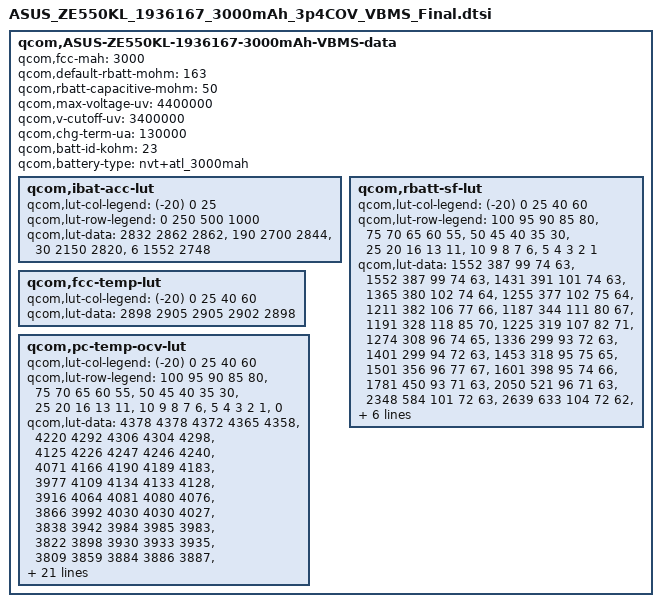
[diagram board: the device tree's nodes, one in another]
 qcom,ASUS-ZE550KL-1936167-3000mAh-VBMS-data {
	qcom,fcc-mah = <3000>;
	qcom,default-rbatt-mohm = <163>;
	qcom,rbatt-capacitive-mohm = <50>;
	qcom,max-voltage-uv = <4400000>;
	qcom,v-cutoff-uv = <3400000>;
	qcom,chg-term-ua = <130000>;
	qcom,batt-id-kohm = <23>;
	qcom,battery-type = "nvt+atl_3000mah";

	qcom,ibat-acc-lut {
		qcom,lut-col-legend = <(-20) 0 25>;
		qcom,lut-row-legend = <0 250 500 1000>;
		qcom,lut-data = <2832 2862 2862>,
				<190 2700 2844>,
				<30 2150 2820>,
				<6 1552 2748>;
	};

	qcom,rbatt-sf-lut {
		qcom,lut-col-legend = <(-20) 0 25 40 60>;
		qcom,lut-row-legend = <100 95 90 85 80>,
				<75 70 65 60 55>,
				<50 45 40 35 30>,
				<25 20 16 13 11>,
				<10 9 8 7 6>,
				<5 4 3 2 1>;
		qcom,lut-data = <1552 387 99 74 63>,
				<1552 387 99 74 63>,
				<1431 391 101 74 63>,
				<1365 380 102 74 64>,
				<1255 377 102 75 64>,
				<1211 382 106 77 66>,
				<1187 344 111 80 67>,
				<1191 328 118 85 70>,
				<1225 319 107 82 71>,
				<1274 308 96 74 65>,
				<1336 299 93 72 63>,
				<1401 299 94 72 63>,
				<1453 318 95 75 65>,
				<1501 356 96 77 67>,
				<1601 398 95 74 66>,
				<1781 450 93 71 63>,
				<2050 521 96 71 63>,
				<2348 584 101 72 63>,
				<2639 633 104 72 62>,
				<2963 678 108 74 63>,
				<3132 702 110 75 64>,
				<3370 728 113 77 66>,
				<3625 742 115 79 67>,
				<3757 733 116 80 69>,
				<4143 757 117 79 69>,
				<4610 793 116 77 65>,
				<5332 836 117 77 65>,
				<6471 898 125 80 67>,
				<8315 995 135 87 72>,
				<13226 1787 184 132 90>;
	};

	qcom,fcc-temp-lut {
		qcom,lut-col-legend = <(-20) 0 25 40 60>;
		qcom,lut-data = <2898 2905 2905 2902 2898>;
	};

	qcom,pc-temp-ocv-lut {
		qcom,lut-col-legend = <(-20) 0 25 40 60>;
		qcom,lut-row-legend = <100 95 90 85 80>,
				<75 70 65 60 55>,
				<50 45 40 35 30>,
				<25 20 16 13 11>,
				<10 9 8 7 6>,
				<5 4 3 2 1>,
				<0>;
		qcom,lut-data = <4378 4378 4372 4365 4358>,
				<4220 4292 4306 4304 4298>,
				<4125 4226 4247 4246 4240>,
				<4071 4166 4190 4189 4183>,
				<3977 4109 4134 4133 4128>,
				<3916 4064 4081 4080 4076>,
				<3866 3992 4030 4030 4027>,
				<3838 3942 3984 3985 3983>,
				<3822 3898 3930 3933 3935>,
				<3809 3859 3884 3886 3887>,
				<3797 3826 3850 3852 3852>,
				<3784 3802 3826 3827 3827>,
				<3771 3788 3804 3806 3806>,
				<3757 3779 3786 3789 3789>,
				<3743 3768 3770 3769 3764>,
				<3726 3752 3753 3746 3738>,
				<3707 3732 3734 3726 3715>,
				<3688 3712 3712 3706 3695>,
				<3670 3696 3693 3688 3677>,
				<3655 3688 3686 3681 3672>,
				<3648 3684 3684 3678 3669>,
				<3636 3680 3682 3676 3667>,
				<3624 3675 3680 3676 3666>,
				<3612 3669 3676 3672 3662>,
				<3592 3658 3668 3660 3652>,
				<3569 3636 3643 3634 3622>,
				<3540 3599 3600 3588 3577>,
				<3494 3544 3542 3528 3518>,
				<3418 3466 3462 3448 3440>,
				<3289 3341 3340 3322 3321>,
				<3000 3000 3000 3000 3000>;
	};
};
